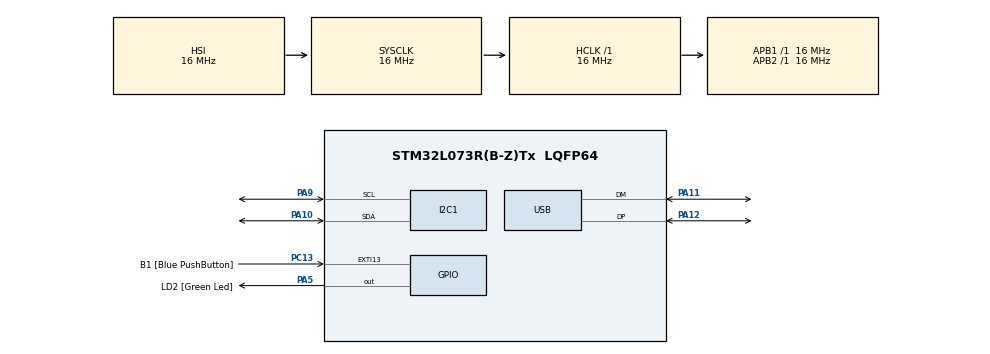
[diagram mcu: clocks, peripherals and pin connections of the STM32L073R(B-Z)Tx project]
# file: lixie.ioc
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I2C1.Timing=0x00303D5B
Mcu.Family=STM32L0
Mcu.Name=STM32L073R(B-Z)Tx
Mcu.Package=LQFP64
NVIC.EXTI4_15_IRQn=true\:0\:0\:false\:false\:true\:true\:true
NVIC.USB_IRQn=true\:0\:0\:false\:false\:true\:false\:true
PA10.Mode=I2C
PA10.Signal=I2C1_SDA
PA11.Mode=Device
PA11.Signal=USB_DM
PA12.Mode=Device
PA12.Signal=USB_DP
PA13.GPIO_Label=TMS
PA13.Mode=Serial_Wire
PA13.Signal=SYS_SWDIO
PA14.GPIO_Label=TCK
PA14.Mode=Serial_Wire
PA14.Signal=SYS_SWCLK
PA5.GPIO_Label=LD2 [Green Led]
PA5.Signal=GPIO_Output
PA9.Mode=I2C
PA9.Signal=I2C1_SCL
PC13.GPIO_Label=B1 [Blue PushButton]
PC13.GPIO_ModeDefaultEXTI=GPIO_MODE_IT_FALLING
PC13.Signal=GPXTI13
ProjectManager.HeapSize=0x200
ProjectManager.StackSize=0x400
ProjectManager.TargetToolchain=STM32CubeIDE
RCC.AHBFreq_Value=16000000
RCC.APB1Freq_Value=16000000
RCC.APB1TimFreq_Value=16000000
RCC.APB2Freq_Value=16000000
RCC.APB2TimFreq_Value=16000000
RCC.HCLKFreq_Value=16000000
RCC.HSE_VALUE=8000000
RCC.HSI16_VALUE=16000000
RCC.HSI48MClockSelection=RCC_USBCLKSOURCE_HSI48
RCC.HSI48_VALUE=48000000
RCC.HSI_VALUE=16000000
RCC.LSE_VALUE=32768
RCC.MSI_VALUE=2097000
RCC.PLLMUL=RCC_PLLMUL_12
RCC.SYSCLKFreq_VALUE=16000000
RCC.SYSCLKSource=RCC_SYSCLKSOURCE_HSI
RCC.VCOOutputFreq_Value=192000000
USB.low_power_enable=DISABLE
USB_DEVICE.APP_RX_DATA_SIZE=1
USB_DEVICE.APP_TX_DATA_SIZE=1
USB_DEVICE.CLASS_NAME_FS=CDC
USB_DEVICE.CONFIGURATION_STRING_CDC_FS=usbserial
USB_DEVICE.INTERFACE_STRING_CDC_FS=usbserial_generic
USB_DEVICE.MANUFACTURER_STRING=frkbmb
USB_DEVICE.PID_CDC_FS=1337
USB_DEVICE.PRODUCT_STRING_CDC_FS=totem
USB_DEVICE.VirtualMode=Cdc
USB_DEVICE.VirtualModeFS=Cdc_FS
VP_USB_DEVICE_VS_USB_DEVICE_CDC_FS.Mode=CDC_FS
board=NUCLEO-L073RZ

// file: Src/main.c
/* USER CODE BEGIN Header */
/**
  ******************************************************************************
  * @file           : main.c
  * @brief          : Main program body
  ******************************************************************************
  * @attention
  *
  * <h2><center>&copy; Copyright (c) 2020 STMicroelectronics.
  * All rights reserved.</center></h2>
  *
  * This software component is licensed by ST under BSD 3-Clause license,
  * the "License"; You may not use this file except in compliance with the
  * License. You may obtain a copy of the License at:
  *                        opensource.org/licenses/BSD-3-Clause
  *
  ******************************************************************************
  */
/* USER CODE END Header */

#include "main.h"
#include "usb_device.h"

/* USER CODE BEGIN Includes */
#include "usbd_cdc_if.h"
#include "lexer.h"
#include "game.h"
#include "power.h"
/* USER CODE END Includes */

I2C_HandleTypeDef hi2c1;

/* USER CODE BEGIN PV */
volatile uint8_t stopState = 0;
/* USER CODE END PV */

void SystemClock_Config(void);
static void MX_GPIO_Init(void);
static void MX_I2C1_Init(void);

int main(void)
{

  /* MCU Configuration--------------------------------------------------------*/

  /* Reset of all peripherals, Initializes the Flash interface and the Systick. */
  HAL_Init();

  /* Configure the system clock */
  SystemClock_Config();

  /* Initialize all configured peripherals */
  MX_GPIO_Init();
  MX_I2C1_Init();
  MX_USB_DEVICE_Init();
  /* USER CODE BEGIN 2 */
  InitGame();
  /* USER CODE END 2 */

  /* Infinite loop */
  /* USER CODE BEGIN WHILE */
  while (1)
  {
	GameLoop();
    /* USER CODE END WHILE */

    /* USER CODE BEGIN 3 */
	if(stopState){
		DeepSleep();
	}

  }
  /* USER CODE END 3 */
}

void SystemClock_Config(void)
{
  RCC_OscInitTypeDef RCC_OscInitStruct = {0};
  RCC_ClkInitTypeDef RCC_ClkInitStruct = {0};
  RCC_PeriphCLKInitTypeDef PeriphClkInit = {0};

  /** Configure the main internal regulator output voltage
  */
  __HAL_PWR_VOLTAGESCALING_CONFIG(PWR_REGULATOR_VOLTAGE_SCALE1);
  /** Initializes the CPU, AHB and APB busses clocks
  */
  RCC_OscInitStruct.OscillatorType = RCC_OSCILLATORTYPE_HSI|RCC_OSCILLATORTYPE_HSI48;
  RCC_OscInitStruct.HSIState = RCC_HSI_ON;
  RCC_OscInitStruct.HSICalibrationValue = RCC_HSICALIBRATION_DEFAULT;
  RCC_OscInitStruct.HSI48State = RCC_HSI48_ON;
  RCC_OscInitStruct.PLL.PLLState = RCC_PLL_NONE;
  if (HAL_RCC_OscConfig(&RCC_OscInitStruct) != HAL_OK)
  {
    Error_Handler();
  }
  /** Initializes the CPU, AHB and APB busses clocks
  */
  RCC_ClkInitStruct.ClockType = RCC_CLOCKTYPE_HCLK|RCC_CLOCKTYPE_SYSCLK
                              |RCC_CLOCKTYPE_PCLK1|RCC_CLOCKTYPE_PCLK2;
  RCC_ClkInitStruct.SYSCLKSource = RCC_SYSCLKSOURCE_HSI;
  RCC_ClkInitStruct.AHBCLKDivider = RCC_SYSCLK_DIV1;
  RCC_ClkInitStruct.APB1CLKDivider = RCC_HCLK_DIV1;
  RCC_ClkInitStruct.APB2CLKDivider = RCC_HCLK_DIV1;

  if (HAL_RCC_ClockConfig(&RCC_ClkInitStruct, FLASH_LATENCY_0) != HAL_OK)
  {
    Error_Handler();
  }
  PeriphClkInit.PeriphClockSelection = RCC_PERIPHCLK_I2C1|RCC_PERIPHCLK_USB;
  PeriphClkInit.I2c1ClockSelection = RCC_I2C1CLKSOURCE_PCLK1;
  PeriphClkInit.UsbClockSelection = RCC_USBCLKSOURCE_HSI48;
  if (HAL_RCCEx_PeriphCLKConfig(&PeriphClkInit) != HAL_OK)
  {
    Error_Handler();
  }
}

static void MX_I2C1_Init(void)
{

  hi2c1.Instance = I2C1;
  hi2c1.Init.Timing = 0x00303D5B;
  hi2c1.Init.OwnAddress1 = 0;
  hi2c1.Init.AddressingMode = I2C_ADDRESSINGMODE_7BIT;
  hi2c1.Init.DualAddressMode = I2C_DUALADDRESS_DISABLE;
  hi2c1.Init.OwnAddress2 = 0;
  hi2c1.Init.OwnAddress2Masks = I2C_OA2_NOMASK;
  hi2c1.Init.GeneralCallMode = I2C_GENERALCALL_DISABLE;
  hi2c1.Init.NoStretchMode = I2C_NOSTRETCH_DISABLE;
  if (HAL_I2C_Init(&hi2c1) != HAL_OK)
  {
    Error_Handler();
  }
  /** Configure Analog filter
  */
  if (HAL_I2CEx_ConfigAnalogFilter(&hi2c1, I2C_ANALOGFILTER_ENABLE) != HAL_OK)
  {
    Error_Handler();
  }
  /** Configure Digital filter
  */
  if (HAL_I2CEx_ConfigDigitalFilter(&hi2c1, 0) != HAL_OK)
  {
    Error_Handler();
  }

}

static void MX_GPIO_Init(void)
{
  GPIO_InitTypeDef GPIO_InitStruct = {0};

  /* GPIO Ports Clock Enable */
  __HAL_RCC_GPIOC_CLK_ENABLE();
  __HAL_RCC_GPIOA_CLK_ENABLE();

  /*Configure GPIO pin Output Level */
  HAL_GPIO_WritePin(LD2_GPIO_Port, LD2_Pin, GPIO_PIN_RESET);

  /*Configure GPIO pin : B1_Pin */
  GPIO_InitStruct.Pin = B1_Pin;
  GPIO_InitStruct.Mode = GPIO_MODE_IT_FALLING;
  GPIO_InitStruct.Pull = GPIO_NOPULL;
  HAL_GPIO_Init(B1_GPIO_Port, &GPIO_InitStruct);

  /*Configure GPIO pin : LD2_Pin */
  GPIO_InitStruct.Pin = LD2_Pin;
  GPIO_InitStruct.Mode = GPIO_MODE_OUTPUT_PP;
  GPIO_InitStruct.Pull = GPIO_NOPULL;
  GPIO_InitStruct.Speed = GPIO_SPEED_FREQ_LOW;
  HAL_GPIO_Init(LD2_GPIO_Port, &GPIO_InitStruct);
  HAL_GPIO_WritePin(LD2_GPIO_Port, LD2_Pin, GPIO_PIN_SET);

  /* EXTI interrupt init*/
  HAL_NVIC_SetPriority(EXTI4_15_IRQn, 0, 0);
  HAL_NVIC_EnableIRQ(EXTI4_15_IRQn);

}

void Error_Handler(void)
{
}

/************************ (C) COPYRIGHT STMicroelectronics *****END OF FILE****/
